[part 6 of 6: packages /DBC_SysDesc_C_CANFD/Pkg_CompuMethod to /DBC_SysDesc_VCU_CAN/Pkg_Units]
AUTOSAR XML (schema 4-2-2)
package /DBC_SysDesc_C_CANFD/Pkg_CompuMethod
  compu method CompuMethod_IBC_CRC_186: raw=phys for phys 0..255
  compu method CompuMethod_IBC_RollingCounter_186: raw=phys for phys 0..15
  compu method CompuMethod_IBC_WheelPressureReliabilityFL: raw=phys for phys 0..1
  compu method CompuMethod_IBC_WheelPressureReliabilityFR: raw=phys for phys 0..1
  compu method CompuMethod_IBC_WheelPressureReliabilityRL: raw=phys for phys 0..1
  compu method CompuMethod_IBC_WheelPressureReliabilityRR: raw=phys for phys 0..1
  compu method CompuMethod_IBC_WheelCylinderPressure_FL: raw=phys*8 for phys 0..255.75
  compu method CompuMethod_IBC_WheelCylinderPressure_FR: raw=phys*8 for phys 0..255.75
  compu method CompuMethod_IBC_WheelCylinderPressure_RL: raw=phys*8 for phys 0..255.75
  compu method CompuMethod_IBC_WheelCylinderPressure_RR: raw=phys*8 for phys 0..255.75
  compu method CompuMethod_IBC_WheelSlipFLVD: raw=phys for phys 0..1
  compu method CompuMethod_IBC_WheelSlipFRVD: raw=phys for phys 0..1
  compu method CompuMethod_IBC_WheelSlipRLVD: raw=phys for phys 0..1
  compu method CompuMethod_IBC_WheelSlipRRVD: raw=phys for phys 0..1
  compu method CompuMethod_IBC_WheelSlipFL: raw=phys+127 for phys -127..127
  compu method CompuMethod_IBC_WheelSlipFR: raw=phys+127 for phys -127..127
  compu method CompuMethod_IBC_WheelSlipRL: raw=phys+127 for phys -127..127
  compu method CompuMethod_IBC_WheelSlipRR: raw=phys+127 for phys -127..127
  compu method CompuMethod_IBC_Slop_Pencent: raw=phys for phys 0..100
  compu method CompuMethod_LMC_CRC_FA: raw=phys for phys 0..255
  compu method CompuMethod_LMC_RollingCounter_FA: raw=phys for phys 0..15
  compu method CompuMethod_LMC_EngTorqDec_Main: raw=phys+400 for phys -400..400
  compu method CompuMethod_LMC_EngTorqDecActive_Main: raw=phys for phys 0..1
  compu method CompuMethod_LMC_AMM_St: raw=phys for phys 0..3
  compu method CompuMethod_LMC_EngTorqInc_Main: raw=phys+400 for phys -400..400
  compu method CompuMethod_LMC_EngTorqIncActive_Main: raw=phys for phys 0..1
  compu method CompuMethod_LMC_EngTorqDec_Sub: raw=phys+400 for phys -400..400
  compu method CompuMethod_LMC_EngTorqDecActive_Sub: raw=phys for phys 0..1
  compu method CompuMethod_LMC_EngTorqInc_Sub: raw=phys+400 for phys -400..400
  compu method CompuMethod_LMC_EngTorqIncActive_Sub: raw=phys for phys 0..1
  compu method CompuMethod_ADDC_CRC_83: raw=phys for phys 0..255
  compu method CompuMethod_ADDC_ACC_AVHReq: raw=phys for phys 0..1
  compu method CompuMethod_ADDC_ACC_HoldSts: raw=phys for phys 0..1
  compu method CompuMethod_ADDC_ACCTargetTrq: raw=phys for phys 0..16383
  compu method CompuMethod_ADDC_ACCTargetTrqVD: raw=phys for phys 0..1
  compu method CompuMethod_ADDC_ACCTargetTrqBrkVD: raw=phys for phys 0..1
  compu method CompuMethod_ADDC_ACCTargetTrqBrk: raw=phys for phys 0..8191
  compu method CompuMethod_ADDC_MAIWarnTrqCtrlFlg: raw=phys for phys 0..7
  compu method CompuMethod_ADDC_RollingCounter_83: raw=phys for phys 0..15
  compu method CompuMethod_ADDC_ACC_FunType: raw=phys for phys 0..3
  compu method CompuMethod_ADDC_ACCMode: raw=phys for phys 0..7
  compu method CompuMethod_ADDC_Driveoff_Request: raw=phys for phys 0..1
  compu method CompuMethod_ADDC_DecToStop: raw=phys for phys 0..1
  compu method CompuMethod_ADDC_ACCAvailable: raw=phys for phys 0..1
  compu method CompuMethod_ADDC_ACCTargetAcc: raw=phys*20+100 for phys -5..7.75
  compu method CompuMethod_ADDC_ACCTargetAccVD: raw=phys for phys 0..1
  compu method CompuMethod_ADDC_ACC_RecordingPulse: raw=phys for phys 0..3
  compu method CompuMethod_ADDC_VehicleSpeedCtlVD: raw=phys for phys 0..1
  compu method CompuMethod_ADDC_VehicleSpeedCtl: raw=phys*10 for phys 0..180
  compu method CompuMethod_ADDC_ACC_EPBReq: raw=phys for phys 0..3
  compu method CompuMethod_ADDC_ACC_VehicleDirectCtl: raw=phys for phys 0..3
  compu method CompuMethod_ADDC_ACC_VehicleDirectCtlVD: raw=phys for phys 0..1
  compu method CompuMethod_ADDC_AEBTargetDec: raw=phys*2000+32000 for phys -16..16
  compu method CompuMethod_ADDC_AEBDecCtrl: raw=phys for phys 0..1
  compu method CompuMethod_ADDC_AEBMode: raw=phys for phys 0..7
  compu method CompuMethod_ADDC_AEBAvailable: raw=phys for phys 0..1
  compu method CompuMethod_ADDC_ACC_VLCCtlReq: raw=phys for phys 0..1
  compu method CompuMethod_ADDC_ACC_OvrdSts: raw=phys for phys 0..1
  compu method CompuMethod_ADDC_RCTB_DecReq: raw=phys for phys 0..1
  compu method CompuMethod_ADDC_RAEB_DecReq: raw=phys for phys 0..1
  compu method CompuMethod_ADDC_MEB_DecReq: raw=phys for phys 0..1
  compu method CompuMethod_LMC_CRC_FD: raw=phys for phys 0..255
  compu method CompuMethod_LMC_RollingCounter_FD: raw=phys for phys 0..15
  compu method CompuMethod_LMC_SysSt: raw=phys for phys 0..3
  compu method CompuMethod_LMC_HSPC_ActiveSt: raw=phys for phys 0..1
  compu method CompuMethod_LMC_FTSC_ActiveSt: raw=phys for phys 0..1
  compu method CompuMethod_LMC_SDRM_ActiveSt: raw=phys for phys 0..1
  compu method CompuMethod_LMC_NSPC_ActiveSt: raw=phys for phys 0..1
  compu method CompuMethod_LMC_EAF_ActiveSt: raw=phys for phys 0..1
  compu method CompuMethod_LMC_SelfCheckSt: raw=phys for phys 0..1
  compu method CompuMethod_LMC_WBDC_ActiveSt: raw=phys for phys 0..3
  compu method CompuMethod_ADDC_CRC_84: raw=phys for phys 0..255
  compu method CompuMethod_ADDC_APS_AVHReq: raw=phys for phys 0..1
  compu method CompuMethod_ADDC_APS_HoldSts: raw=phys for phys 0..1
  compu method CompuMethod_ADDC_APSTargetTrqBrkVD: raw=phys for phys 0..1
  compu method CompuMethod_ADDC_APSTargetTrqBrk: raw=phys for phys 0..8191
  compu method CompuMethod_ADDC_APSTargetTrqVD: raw=phys for phys 0..1
  compu method CompuMethod_ADDC_APSTargetTrq: raw=phys for phys 0..16383
  compu method CompuMethod_ADDC_safety_valid: raw=phys for phys 0..1
  compu method CompuMethod_ADDC_rearsafety_level: raw=phys for phys 0..7
  compu method CompuMethod_ADDC_frontsafety_level: raw=phys for phys 0..7
  compu method CompuMethod_ADDC_rightsafety_level: raw=phys for phys 0..7
  compu method CompuMethod_ADDC_leftsafety_level: raw=phys for phys 0..7
  compu method CompuMethod_ADDC_RollingCounter_84: raw=phys for phys 0..15
  compu method CompuMethod_ADDC_APS_EnableReq: raw=phys for phys 0..1
  compu method CompuMethod_ADDC_APS_WorkSts: raw=phys for phys 0..1
  compu method CompuMethod_ADDC_APS_PDCVehicleDirectCtlVD: raw=phys for phys 0..1
  compu method CompuMethod_ADDC_APS_VehicleSpeedCtlVD: raw=phys for phys 0..1
  compu method CompuMethod_ADDC_APS_PDC_VehicleDirectCtl: raw=phys for phys 0..3
  compu method CompuMethod_ADDC_APS_PDC_SWAngCtl: raw=phys*50+32500 for phys -650..650
  compu method CompuMethod_ADDC_APS_ParkingReq: raw=phys for phys 0..3
  compu method CompuMethod_ADDC_APS_EmergenceBrake: raw=phys for phys 0..1
  compu method CompuMethod_ADDC_APS_TargetAccVD: raw=phys for phys 0..1
  compu method CompuMethod_ADDC_APS_TargetAcc: raw=phys*20+140 for phys -7..5
  compu method CompuMethod_ADDC_APS_VehicleSpeedCtl: raw=phys*8 for phys 0..7.875
  compu method CompuMethod_ADDC_APS_DecToStop: raw=phys for phys 0..1
  compu method CompuMethod_ADDC_APS_Driveoff_Request: raw=phys for phys 0..1
  compu method CompuMethod_ADDC_APS_FuncType: raw=phys for phys 0..7
  compu method CompuMethod_ADDC_APS_Available: raw=phys for phys 0..1
  compu method CompuMethod_IBC_CRC_B1: raw=phys for phys 0..255
  compu method CompuMethod_IBC_RollingCounter_B1: raw=phys for phys 0..15
  compu method CompuMethod_IBC_EngTorqDec_Main: raw=phys+400 for phys -400..400
  compu method CompuMethod_IBC_EngTorqDecActive_Main: raw=phys for phys 0..1
  compu method CompuMethod_IBC_EngTorqInc_Main: raw=phys+400 for phys -400..400
  compu method CompuMethod_IBC_EngTorqIncActive_Main: raw=phys for phys 0..1
  compu method CompuMethod_IBC_EngTorqDec_Sub: raw=phys+400 for phys -400..400
  compu method CompuMethod_IBC_EngTorqDecActive_Sub: raw=phys for phys 0..1
  compu method CompuMethod_IBC_EngTorqInc_Sub: raw=phys+400 for phys -400..400
  compu method CompuMethod_IBC_EngTorqIncActive_Sub: raw=phys for phys 0..1
  compu method CompuMethod_IBC_EngTorqDec_MainR: raw=phys+400 for phys -400..400
  compu method CompuMethod_IBC_EngTorqDecActive_MainR: raw=phys for phys 0..1
  compu method CompuMethod_IBC_EngTorqInc_MainR: raw=phys+400 for phys -400..400
  compu method CompuMethod_IBC_EngTorqIncActive_MainR: raw=phys for phys 0..1
  compu method CompuMethod_IBC_CRC_227: raw=phys for phys 0..255
  compu method CompuMethod_IBC_RollingCounter_227: raw=phys for phys 0..15
  compu method CompuMethod_IBC_EPB_FailStatus: raw=phys for phys 0..3
  compu method CompuMethod_IBC_EPB_Status: raw=phys for phys 0..7
  compu method CompuMethod_IBC_EPB_DrumMode: raw=phys for phys 0..1
  compu method CompuMethod_IBC_EPB_AchievedClampForce: raw=phys for phys 0..255
  compu method CompuMethod_IBC_EPB_FailureLamp: raw=phys for phys 0..3
  compu method CompuMethod_IBC_EPB_ActuatorStateLeft: raw=phys for phys 0..3
  compu method CompuMethod_IBC_EPB_ActuatorStateRight: raw=phys for phys 0..3
  compu method CompuMethod_IBC_EPB_HostAvailabilityLeft: raw=phys for phys 0..3
  compu method CompuMethod_IBC_EPB_HostAvailabilityRight: raw=phys for phys 0..3
  compu method CompuMethod_EPS_CRC_18D: raw=phys for phys 0..255
  compu method CompuMethod_EPS_RollingCounter_18D: raw=phys for phys 0..15
  compu method CompuMethod_EPS_Fault: raw=phys for phys 0..1
  compu method CompuMethod_EPS_CalibrationSts: raw=phys for phys 0..1
  compu method CompuMethod_EPS_FailureSts: raw=phys for phys 0..1
  compu method CompuMethod_EPS_SteeringAngleValidData: raw=phys for phys 0..1
  compu method CompuMethod_EPS_SteeringAngleSpeedValidData: raw=phys for phys 0..1
  compu method CompuMethod_EPS_SteerWheelAngle: raw=phys*50+32500 for phys -650..650
  compu method CompuMethod_EPS_SteerWheelRotSpd: raw=phys*0.25 for phys 0..1016
  compu method CompuMethod_EPS_SelfCheckSt: raw=phys for phys 0..1
  compu method CompuMethod_EPS_AssistanceSts: raw=phys for phys 0..2
  compu method CompuMethod_IBC_CRC_182: raw=phys for phys 0..255
  compu method CompuMethod_IBC_RollingCounter_182: raw=phys for phys 0..15
  compu method CompuMethod_IBC_VehicleSpeed: raw=phys*100 for phys 0..450
  compu method CompuMethod_IBC_VehicleSpeedVD: raw=phys for phys 0..1
  compu method CompuMethod_IBC_ABSActive: raw=phys for phys 0..1
  compu method CompuMethod_IBC_ABSFailed: raw=phys for phys 0..1
  compu method CompuMethod_IBC_TCSActive: raw=phys for phys 0..1
  compu method CompuMethod_IBC_TCSFailed: raw=phys for phys 0..1
  compu method CompuMethod_IBC_ESCFunctionStatus: raw=phys for phys 0..1
  compu method CompuMethod_IBC_BrakeForce: raw=phys for phys 0..1
  compu method CompuMethod_IBC_Vehiclestandstill: raw=phys for phys 0..1
  compu method CompuMethod_IBC_EBDFailed: raw=phys for phys 0..1
  compu method CompuMethod_IBC_EBDActive: raw=phys for phys 0..1
  compu method CompuMethod_IBC_VDCActive: raw=phys for phys 0..1
  compu method CompuMethod_IBC_VDCFailed: raw=phys for phys 0..1
  compu method CompuMethod_IBC_EDCActive: raw=phys for phys 0..1
  compu method CompuMethod_IBC_EDCFailed: raw=phys for phys 0..1
  compu method CompuMethod_IBC_SystemInitializeStatus: raw=phys for phys 0..1
  compu method CompuMethod_IBC_BTCSActive: raw=phys for phys 0..1
  compu method CompuMethod_IBC_ETCSActive: raw=phys for phys 0..1
  compu method CompuMethod_IBC_ARPActive: raw=phys for phys 0..1
  compu method CompuMethod_IBC_VCU_DrumMode: raw=phys for phys 0..1
  compu method CompuMethod_IBC_EscapeModeSts: raw=phys for phys 0..1
  compu method CompuMethod_IBC_CRC_183: raw=phys for phys 0..255
  compu method CompuMethod_IBC_RollingCounter_183: raw=phys for phys 0..15
  compu method CompuMethod_IBC_RecuBrakeTorqueRequest: raw=phys for phys 0..32767
  compu method CompuMethod_IBC_RecuBrakeTorqueRequest_Q: raw=phys for phys 0..3
  compu method CompuMethod_IBC_sOutputRodDriverPer_Q: raw=phys for phys 0..2
  compu method CompuMethod_IBC_BrakePedalApplied_Q: raw=phys for phys 0..3
  compu method CompuMethod_IBC_HydraTorqTgtAct_Q: raw=phys for phys 0..2
  compu method CompuMethod_IBC_HydraTorqTgtAct: raw=phys for phys 0..32767
  compu method CompuMethod_IBC_BrakePedalApplied: raw=phys for phys 0..1
  compu method CompuMethod_IBC_sOutputRodDriverPer: raw=phys for phys 0..100
  compu method CompuMethod_IBC_HydraTorqAvailable: raw=phys for phys 0..1
  compu method CompuMethod_IBC_CtrlMode: raw=phys for phys 0..7
  compu method CompuMethod_IBC_QDC_HydraTorqTgt: raw=phys for phys 0..1
  compu method CompuMethod_IBC_InPutRodDriver: raw=phys*78.125+390.625 for phys -5..47
  compu method CompuMethod_IBC_InPutRodDriver_Q: raw=phys for phys 0..3
  compu method CompuMethod_IBC_SystemAssistedStatus: raw=phys for phys 0..7
  compu method CompuMethod_IBC_EngTorq_VLC_Vaild: raw=phys for phys 0..1
  compu method CompuMethod_IBC_EngTorq_VLC: raw=phys+6000 for phys -6000..10000
  compu method CompuMethod_IBC_BrkTorq_VLC: raw=phys+32767 for phys -32767..0
  compu method CompuMethod_IBC_BrkTorq_VLC_Vaild: raw=phys for phys 0..1
  compu method CompuMethod_ACU_CRC_233: raw=phys for phys 0..255
  compu method CompuMethod_ACU_RollingCounter_233: raw=phys for phys 0..15
  compu method CompuMethod_ACU_LateralAcce: raw=phys*32+512 for phys -16..15.90625
  compu method CompuMethod_ACU_LongitAcce: raw=phys*32+512 for phys -16..15.90625
  compu method CompuMethod_ACU_LateralAcceValid: raw=phys for phys 0..1
  compu method CompuMethod_ACU_LongitAcceValid: raw=phys for phys 0..1
  compu method CompuMethod_ACU_SensorCalSt: raw=phys for phys 0..1
  compu method CompuMethod_ACU_YawRate: raw=phys*100+8191 for phys -81.91..81.91
  compu method CompuMethod_ACU_YawRateValid: raw=phys for phys 0..1
  compu method CompuMethod_IBC_CRC_184: raw=phys for phys 0..255
  compu method CompuMethod_IBC_RollingCounter_184: raw=phys for phys 0..15
  compu method CompuMethod_IBC_FLWheelSpeedKPH: raw=phys*100 for phys 0..450
  compu method CompuMethod_IBC_FRWheelSpeedKPH: raw=phys*100 for phys 0..450
  compu method CompuMethod_IBC_RLWheelSpeedKPH: raw=phys*100 for phys 0..450
  compu method CompuMethod_IBC_RRWheelSpeedKPH: raw=phys*100 for phys 0..450
  compu method CompuMethod_IBC_FLWheelDirection: raw=phys for phys 0..3
  compu method CompuMethod_IBC_FRWheelDirection: raw=phys for phys 0..3
  compu method CompuMethod_IBC_RLWheelDirection: raw=phys for phys 0..3
  compu method CompuMethod_IBC_RRWheelDirection: raw=phys for phys 0..3
  compu method CompuMethod_IBC_FLWheelSpeedVD: raw=phys for phys 0..1
  compu method CompuMethod_IBC_FRWheelSpeedVD: raw=phys for phys 0..1
  compu method CompuMethod_IBC_RLWheelSpeedVD: raw=phys for phys 0..1
  compu method CompuMethod_IBC_RRWheelSpeedVD: raw=phys for phys 0..1
  compu method CompuMethod_IBC_FLWheelSpeedRC: raw=phys for phys 0..4094
  compu method CompuMethod_IBC_FRWheelSpeedRC: raw=phys for phys 0..4094
  compu method CompuMethod_IBC_RLWheelSpeedRC: raw=phys for phys 0..4094
  compu method CompuMethod_IBC_RRWheelSpeedRC: raw=phys for phys 0..4094
  compu method CompuMethod_IBC_DiscTemperatureFL: raw=phys for phys 0..7
  compu method CompuMethod_IBC_DiscTemperatureFLVD: raw=phys for phys 0..1
  compu method CompuMethod_IBC_DiscTemperatureFR: raw=phys for phys 0..7
  compu method CompuMethod_IBC_DiscTemperatureFRVD: raw=phys for phys 0..1
  compu method CompuMethod_IBC_DiscTemperatureRL: raw=phys for phys 0..7
  compu method CompuMethod_IBC_DiscTemperatureRLVD: raw=phys for phys 0..1
  compu method CompuMethod_IBC_DiscTemperatureRR: raw=phys for phys 0..7
  compu method CompuMethod_IBC_DiscTemperatureRRVD: raw=phys for phys 0..1
  compu method CompuMethod_FSC_CRC_142: raw=phys for phys 0..255
  compu method CompuMethod_FSC_RollingCounter_142: raw=phys for phys 0..15
  compu method CompuMethod_FSC_LCC_Mode: raw=phys for phys 0..7
  compu method CompuMethod_IBC_CRC_185: raw=phys for phys 0..255
  compu method CompuMethod_IBC_RollingCounter_185: raw=phys for phys 0..15
  compu method CompuMethod_IBC_PlungerPressure: raw=phys*8 for phys 0..255.75
  compu method CompuMethod_IBC_PlungerPressure_Q: raw=phys for phys 0..1
  compu method CompuMethod_IBC_SimulatorPressure: raw=phys*8 for phys 0..255.75
  compu method CompuMethod_IBC_SimulatorPressure_Q: raw=phys for phys 0..1
  compu method CompuMethod_IBC_HMI_WarningOn: raw=phys for phys 0..3
  compu method CompuMethod_IBC_MIL_WarningOn: raw=phys for phys 0..1
  compu method CompuMethod_IBC_LongitAcceAct: raw=phys*32+512 for phys -16..15.90625
  compu method CompuMethod_IBC_LongitAcceActValid: raw=phys for phys 0..1
  compu method CompuMethod_IBC_brakeFluidWarning: raw=phys for phys 0..3
  compu method CompuMethod_IBC_SCM_Active: raw=phys for phys 0..1
  compu method CompuMethod_IBC_SCM_Failed: raw=phys for phys 0..1
  compu method CompuMethod_IBC_CDPAvailable: raw=phys for phys 0..1
  compu method CompuMethod_IBC_CDPIntervention: raw=phys for phys 0..1
  compu method CompuMethod_IBC_AEB_active: raw=phys for phys 0..1
  compu method CompuMethod_IBC_AEBdecAvailable: raw=phys for phys 0..1
  compu method CompuMethod_IBC_AVHStatus: raw=phys for phys 0..3
  compu method CompuMethod_IBC_AVHAvailable: raw=phys for phys 0..1
  compu method CompuMethod_IBC_HHCActive: raw=phys for phys 0..1
  compu method CompuMethod_IBC_HHCFailed: raw=phys for phys 0..1
  compu method CompuMethod_IBC_CDD_Available_APA: raw=phys for phys 0..1
  compu method CompuMethod_IBC_CDD_Active_APA: raw=phys for phys 0..1
  compu method CompuMethod_IBC_CDD_Available_ACC: raw=phys for phys 0..1
  compu method CompuMethod_IBC_CDD_Active_ACC: raw=phys for phys 0..1
  compu method CompuMethod_IBC_HDCStatus: raw=phys for phys 0..3
  compu method CompuMethod_IBC_HDCAvailable: raw=phys for phys 0..1
  compu method CompuMethod_IBC_CSTStatus: raw=phys for phys 0..3
  compu method CompuMethod_IBC_CSTAvailable: raw=phys for phys 0..1
  compu method CompuMethod_IBC_VLC_Available_ACC: raw=phys for phys 0..1
  compu method CompuMethod_IBC_VLC_Active_ACC: raw=phys for phys 0..1
  compu method CompuMethod_IBC_VLC_Available_APA: raw=phys for phys 0..1
  compu method CompuMethod_IBC_VLC_Active_APA: raw=phys for phys 0..1
  compu method CompuMethod_IBC_VehicleHoldStatus: raw=phys for phys 0..3
  compu method CompuMethod_IBC_DrvrBrkTqAtWhlsReqd: raw=phys for phys 0..32767
  compu method CompuMethod_ACU_CRC_2A3: raw=phys for phys 0..255
  compu method CompuMethod_ACU_Trigger: raw=phys for phys 0..1
  compu method CompuMethod_ACU_RollingCounter_2A3: raw=phys for phys 0..15
  compu method CompuMethod_ACU_TotalCrashOutputSts: raw=phys for phys 0..1
  compu method CompuMethod_ACU_SelfCheckSt: raw=phys for phys 0..1
  compu method CompuMethod_ACU_FLSeatBeltRSt: raw=phys for phys 0..3
  compu method CompuMethod_ACU_FRSeatBeltRSt: raw=phys for phys 0..3
  compu method CompuMethod_ICU_CRC_24D: raw=phys for phys 0..255
  compu method CompuMethod_ICU_SpeedConversionCoefficient: raw=phys for phys 0..3
  compu method CompuMethod_ICU_RollingCounter_24D: raw=phys for phys 0..15
  compu method CompuMethod_ICU_CCSFunctionStatus: raw=phys for phys 0..1
  compu method CompuMethod_ICU_CruiseVehicleSpeedCtl: raw=phys*100 for phys 0..450
  compu method CompuMethod_ICU_VehicleScreenSpeed: raw=phys for phys 0..450
  compu method CompuMethod_ICU_VehicleSpeedUnit: raw=phys for phys 0..1
  compu method CompuMethod_ICU_ACCFunctionStatus: raw=phys for phys 0..1
  compu method CompuMethod_ICU_LCCFunctionStatus: raw=phys for phys 0..1
  compu method CompuMethod_IVI_LPedalMode: raw=phys for phys 0..1
  compu method CompuMethod_BCM_CRC_290: raw=phys for phys 0..255
  compu method CompuMethod_BCM_RRDoorSts_ID290_CCAN: raw=phys for phys 0..1
  compu method CompuMethod_BCM_RLDoorSts_ID290_CCAN: raw=phys for phys 0..1
  compu method CompuMethod_BCM_RollingCounter_290: raw=phys for phys 0..15
  compu method CompuMethod_BCM_HazardSwtSts: raw=phys for phys 0..1
  compu method CompuMethod_BCM_DrOC_PPD_Status: raw=phys for phys 0..3
  compu method CompuMethod_BCM_FLOC_PPD_Status: raw=phys for phys 0..3
  compu method CompuMethod_BCM_FROC_PPD_Status: raw=phys for phys 0..3
  compu method CompuMethod_BCM_DriverDoorSts_ID290_CCAN: raw=phys for phys 0..1
  compu method CompuMethod_BCM_DriverDoorSts_VD: raw=phys for phys 0..1
  compu method CompuMethod_BCM_FLDoorSts_ID290_CCAN: raw=phys for phys 0..1
  compu method CompuMethod_BCM_FRDoorSts_ID290_CCAN: raw=phys for phys 0..1
  compu method CompuMethod_BCM_BackDoorSts_ID290_CCAN: raw=phys for phys 0..1
  compu method CompuMethod_BCM_FrontCoverSts: raw=phys for phys 0..1
  compu method CompuMethod_BCM_HazardSwtOpenSts: raw=phys for phys 0..1
  compu method CompuMethod_BCM_BrakeFluidLevel: raw=phys for phys 0..3
  compu method CompuMethod_BCM_ON2BRelaySts_ID290_CCAN: raw=phys for phys 0..1
  compu method CompuMethod_BCM_ON2CRelaySts_ID290_CCAN: raw=phys for phys 0..1
  compu method CompuMethod_BCM_AlarmMode_C: raw=phys for phys 0..3
  compu method CompuMethod_LMC_LSFCActiveSt: raw=phys for phys 0..3
  compu method CompuMethod_LMC_EngTorqDec_Main_R: raw=phys+400 for phys -400..400
  compu method CompuMethod_LMC_EngTorqDecActive_Main_R: raw=phys for phys 0..1
  compu method CompuMethod_LMC_EngTorqInc_Main_R: raw=phys+400 for phys -400..400
  compu method CompuMethod_LMC_EngTorqIncActive_Main_R: raw=phys for phys 0..1
  compu method CompuMethod_IVI_CRC_331: raw=phys for phys 0..255
  compu method CompuMethod_IVI_RollingCounter_331: raw=phys for phys 0..15
  compu method CompuMethod_IVI_EPBRequst: raw=phys for phys 0..3
  compu method CompuMethod_IVI_TerrainMatchMode: raw=phys for phys 0..7
  compu method CompuMethod_IVI_LPedalModeSW: raw=phys for phys 0..1
  compu method CompuMethod_IVI_AVHSw_X: raw=phys for phys 0..3
  compu method CompuMethod_IVI_ESCSw_X: raw=phys for phys 0..3
  compu method CompuMethod_IVI_HDCSw_X: raw=phys for phys 0..3
  compu method CompuMethod_IVI_CSTSw_X: raw=phys for phys 0..3
  compu method CompuMethod_IVI_AutoAllRoad: raw=phys for phys 0..7
  compu method CompuMethod_IVI_CampingMode_SW: raw=phys for phys 0..1
  compu method CompuMethod_IVI_BraPedMod: raw=phys for phys 0..3
  compu method CompuMethod_IVI_SlowspeedSmartCtrl: raw=phys for phys 0..1
  compu method CompuMethod_IVI_TrailerModeCtrl: raw=phys for phys 0..1
  compu method CompuMethod_IVI_EscapeMode_SW: raw=phys for phys 0..1
  compu method CompuMethod_IVI_PowerSavingModeReq: raw=phys for phys 0..3
  compu method CompuMethod_IVI_SelfAdaptionDriveSW: raw=phys for phys 0..1
  compu method CompuMethod_IVI_CmpUTurnStartUI: raw=phys for phys 0..1
  compu method CompuMethod_IVI_CmpUTurnLockWhlUI: raw=phys for phys 0..7
  compu method CompuMethod_IVI_CmpUTurnTarDirUI: raw=phys for phys 0..3
  compu method CompuMethod_IVI_CmpUTurnTarAngleUI: raw=phys for phys 0..511
  compu method CompuMethod_IVI_CmpUTurnReq: raw=phys for phys 0..3
  compu method CompuMethod_ICU_CRC_332: raw=phys for phys 0..255
  compu method CompuMethod_ICU_RollingCounter_332: raw=phys for phys 0..15
  compu method CompuMethod_ICU_AEB_SW: raw=phys for phys 0..1
  compu method CompuMethod_ICU_ISA_controlSW: raw=phys for phys 0..1
  compu method CompuMethod_ICU_SLIF_SW: raw=phys for phys 0..1
  compu method CompuMethod_ICU_SLWF_SW: raw=phys for phys 0..1
  compu method CompuMethod_VCU_CRC_B6: raw=phys for phys 0..255
  compu method CompuMethod_VCU_TVTest2: raw=phys for phys 0..1048575
  compu method CompuMethod_VCU_VPE_Test1: raw=phys for phys 0..4095
  compu method CompuMethod_VCU_VPE_Test2: raw=phys for phys 0..127
  compu method CompuMethod_VCU_TVTest1: raw=phys for phys 0..32767
  compu method CompuMethod_VCU_RollingCounter_B6: raw=phys for phys 0..15
  compu method CompuMethod_VCU_MDrvRequestTorque_IDB6_CCAN: raw=phys*10+5000 for phys -500..500
  compu method CompuMethod_VCU_MDriverRequireTorque: raw=phys*10+5000 for phys -500..500
  compu method CompuMethod_VCU_SDrvRequestTorque_IDB6_CCAN: raw=phys*10+5000 for phys -500..500
  compu method CompuMethod_VCU_SDriverRequireTorque: raw=phys*10+5000 for phys -500..500
  compu method CompuMethod_VCU_ThrottlePosition_IDB6_CCAN: raw=phys*2.544529262 for phys 0..100
  compu method CompuMethod_VCU_AccPedalValid_IDB6_CCAN: raw=phys for phys 0..1
  compu method CompuMethod_VCU_BrakeSysFault_IDB6_CCAN: raw=phys for phys 0..1
  compu method CompuMethod_VCU_BrakeLightReq: raw=phys for phys 0..1
  compu method CompuMethod_VCU_BrakePedalSts: raw=phys for phys 0..1
  compu method CompuMethod_VCU_BrakePedalStsValid: raw=phys for phys 0..1
  compu method CompuMethod_VCU_GearLevelPosSts_IDB6_CCAN: raw=phys for phys 0..3
  compu method CompuMethod_VCU_GearLeverValid_IDB6_CCAN: raw=phys for phys 0..1
  compu method CompuMethod_VCU_BrakeFirstSts: raw=phys for phys 0..1
  compu method CompuMethod_VCU_DeliveryModeSts_IDB6_CCAN: raw=phys for phys 0..1
  compu method CompuMethod_VCU_MRDrvRequestTorque_IDB6_CCAN: raw=phys*10 for phys -500..500
  compu method CompuMethod_VCU_MRDriverRequireTorque: raw=phys*10 for phys -500..500
  compu method CompuMethod_VCU_CRC_B7: raw=phys for phys 0..255
  compu method CompuMethod_VCU_KeepWorkModeFlag: raw=phys for phys 0..1
  compu method CompuMethod_VCU_MAI_Active: raw=phys for phys 0..1
  compu method CompuMethod_VCU_MAI_Available: raw=phys for phys 0..1
  compu method CompuMethod_VCU_GetCrashStsReq: raw=phys for phys 0..1
  compu method CompuMethod_VCU_ADASPosTorqueCap_VD: raw=phys for phys 0..1
  compu method CompuMethod_VCU_ADASPosTorqueCap: raw=phys for phys 0..16383
  compu method CompuMethod_VCU_RollingCounter_B7: raw=phys for phys 0..15
  compu method CompuMethod_VCU_Vehicle_Warning_IDB7_CCAN: raw=phys for phys 0..3
  compu method CompuMethod_VCU_VehicleSts_IDB7_CCAN: raw=phys for phys 0..1
  compu method CompuMethod_VCU_PowerReduceReq: raw=phys for phys 0..3
  compu method CompuMethod_VCU_ParkingReqToEPB_VD: raw=phys for phys 0..3
  compu method CompuMethod_VCU_ParkingReqToEPB: raw=phys for phys 0..3
  compu method CompuMethod_VCU_ACCAvailable: raw=phys for phys 0..3
  compu method CompuMethod_VCU_ACCActiveSts: raw=phys for phys 0..1
  compu method CompuMethod_VCU_Active_APS: raw=phys for phys 0..1
  compu method CompuMethod_VCU_Available_APS: raw=phys for phys 0..1
  compu method CompuMethod_VCU_ESCActive: raw=phys for phys 0..1
  compu method CompuMethod_VCU_ESCTorqReqAvailability_Rear: raw=phys for phys 0..1
  compu method CompuMethod_VCU_AutoHold_ibit: raw=phys for phys 0..1
  compu method CompuMethod_VCU_VehicleSpeedVD: raw=phys for phys 0..3
  compu method CompuMethod_VCU_CCSStatus: raw=phys for phys 0..3
  compu method CompuMethod_VCU_AutoDriveRequest: raw=phys for phys 0..3
  compu method CompuMethod_VCU_CCSAllow: raw=phys for phys 0..1
  compu method CompuMethod_VCU_VlcHoldSts: raw=phys for phys 0..1
  compu method CompuMethod_VCU_HoldReqSts: raw=phys for phys 0..3
  compu method CompuMethod_VCU_HoldReqStsValid: raw=phys for phys 0..1
  compu method CompuMethod_VCU_DriverAssistProhibitSts_IDB7_CCAN: raw=phys for phys 0..1
  compu method CompuMethod_VCU_SpeedLimitedSts: raw=phys for phys 0..1
  compu method CompuMethod_VCU_SpeedLimitedValue: raw=phys for phys 0..254
  compu method CompuMethod_VCU_TheoAccePedalPercent: raw=phys*2.544529262 for phys 0..100
  compu method CompuMethod_VCU_RecuBrakeTorqueCap: raw=phys for phys 0..32767
  compu method CompuMethod_VCU_RecuBrakeTorqueAct: raw=phys for phys 0..32767
  compu method CompuMethod_VCU_TheoAccePedalValid: raw=phys for phys 0..1
  compu method CompuMethod_VCU_HydraTorqTgt: raw=phys for phys 0..32767
  compu method CompuMethod_VCU_RecuBrakeTorqueActDrag: raw=phys for phys 0..32767
  compu method CompuMethod_VCU_ESCTorqReqAvailability_Frnt: raw=phys for phys 0..1
  compu method CompuMethod_VCU_RecuBrakeTorqueCap_Q: raw=phys for phys 0..3
  compu method CompuMethod_VCU_RecuBrakeTorqueAct_Q: raw=phys for phys 0..3
  compu method CompuMethod_VCU_HydraTorqTgt_Q: raw=phys for phys 0..3
  compu method CompuMethod_VCU_RecuBrakeTorqueActDrag_Q: raw=phys for phys 0..3
  compu method CompuMethod_VCU_RecuBrakeTorqueTarget_Drag: raw=phys for phys 0..32767
  compu method CompuMethod_VCU_PreventVehSlipSts: raw=phys for phys 0..1
  compu method CompuMethod_VCU_RecuBrakeTorqueTarget_Drag_Q: raw=phys for phys 0..3
  compu method CompuMethod_VCU_AllMotWhlTrqFB: raw=phys+6000 for phys -6000..10000
  compu method CompuMethod_VCU_AllMotWhlTrqFB_VD: raw=phys for phys 0..1
  compu method CompuMethod_VCU_TorqueMax_Sub: raw=phys for phys 0..32766
  compu method CompuMethod_VCU_TorqueMax_Sub_VD: raw=phys for phys 0..1
  compu method CompuMethod_VCU_TorqueMax_Main_VD: raw=phys for phys 0..1
  compu method CompuMethod_VCU_LSFC_Allow: raw=phys for phys 0..1
  compu method CompuMethod_VCU_LSFC_Active: raw=phys for phys 0..1
  compu method CompuMethod_VCU_MGCUWorkMode_C: raw=phys for phys 0..3
  compu method CompuMethod_VCU_AllRoadSts: raw=phys for phys 0..7
  compu method CompuMethod_VCU_CmpUTurnAllow: raw=phys for phys 0..1
  compu method CompuMethod_VCU_CmpUTurnSts: raw=phys for phys 0..3
  compu method CompuMethod_VCU_AllowCmpUTurnStartFlag: raw=phys for phys 0..1
  compu method CompuMethod_VCU_CmpUTurnLockWhl: raw=phys for phys 0..7
  compu method CompuMethod_VCU_CmpUTurnActAngle: raw=phys for phys 0..511
  compu method CompuMethod_VCU_CmpUTurnActSpinSpd: raw=phys for phys 0..15
  compu method CompuMethod_VCU_CmpUTurnFltHMI: raw=phys for phys 0..15
  compu method CompuMethod_VCU_TorqueMax_Main: raw=phys for phys 0..32766
  compu method CompuMethod_VCU_EscapeModeSts: raw=phys for phys 0..1
  compu method CompuMethod_VCU_MCUSWorkFailMsg: raw=phys for phys 0..7
  compu method CompuMethod_VCU_EscapeWorkFailMsg: raw=phys for phys 0..7
  compu method CompuMethod_VCU_REClutchFltMsg: raw=phys for phys 0..3
  compu method CompuMethod_IBC_CRC_136: raw=phys for phys 0..255
  compu method CompuMethod_IBC_RollingCounter_136: raw=phys for phys 0..15
  compu method CompuMethod_IBC_ModeMinEDrvTar_FA: raw=phys for phys 0..3
  compu method CompuMethod_IBC_ModeMinEDrvTar_RA: raw=phys for phys 0..3
  compu method CompuMethod_IBC_ModeMaxEDrvTar_FA: raw=phys for phys 0..3
  compu method CompuMethod_IBC_ModeMaxEDrvTar_RA: raw=phys for phys 0..3
  compu method CompuMethod_IBC_torque_distribution_RA_Vaild: raw=phys for phys 0..1
  compu method CompuMethod_IBC_torque_distribution_RA: raw=phys for phys 0..255
  compu method CompuMethod_IBC_mTar_FA: raw=phys for phys 0..65535
  compu method CompuMethod_IBC_mTar_RA: raw=phys for phys 0..65535
  compu method CompuMethod_IBC_iLDC_SWInfo: raw=phys for phys 0..255
  compu method CompuMethod_IBC_Variant_Signal: raw=phys for phys 0..255
  compu method CompuMethod_IBC_nTarMax_FA: raw=phys*64+32768 for phys -512..511
  compu method CompuMethod_IBC_nTarMax_RA: raw=phys*64+32768 for phys -512..511
  compu method CompuMethod_IBC_nTarMin_FA: raw=phys*64+32768 for phys -512..511
  compu method CompuMethod_IBC_nTarMin_RA: raw=phys*64+32768 for phys -512..511
  compu method CompuMethod_MCUM_CRC_135: raw=phys for phys 0..255
  compu method CompuMethod_MCUM_RollingCounter_135: raw=phys for phys 0..15
  compu method CompuMethod_MCUM_LDC_SWInfo: raw=phys for phys 0..65534
  compu method CompuMethod_MCUM_LDC_MTarOut_FA: raw=phys+30000 for phys -30000..30000
  compu method CompuMethod_MCUM_LDC_MTarOut_RA: raw=phys+30000 for phys -30000..30000
  compu method CompuMethod_MCUM_LDC_Available_FA: raw=phys for phys 0..1
  compu method CompuMethod_MCUM_LDC_OperationMode_FA: raw=phys for phys 0..7
  compu method CompuMethod_MCUM_LDC_Available_RA: raw=phys for phys 0..1
  compu method CompuMethod_MCUM_LDC_OperationMode_RA: raw=phys for phys 0..7
  compu method CompuMethod_MCUM_RTE_Exchange_Signal_Status: raw=phys for phys 0..255
  compu method CompuMethod_MCUM_MTarIn_FA: raw=phys for phys 0..65535
  compu method CompuMethod_MCUM_MTarIn_RA: raw=phys for phys 0..65535
  compu method CompuMethod_MCUM_InputQF_FA: raw=phys for phys 0..1
  compu method CompuMethod_MCUM_InputQF_RA: raw=phys for phys 0..1
package /DBC_SysDesc_C_CANFD/Pkg_Units
  unit NOUNIT
package /DBC_SysDesc_VCU_CAN/Pkg_Cluster
  can cluster VCU_CAN: baudrate=500000, protocol-name=CAN
    can physical channel VCU_CAN_Channel: comm-connectors=[Conn_VCU_CAN_MVCU]
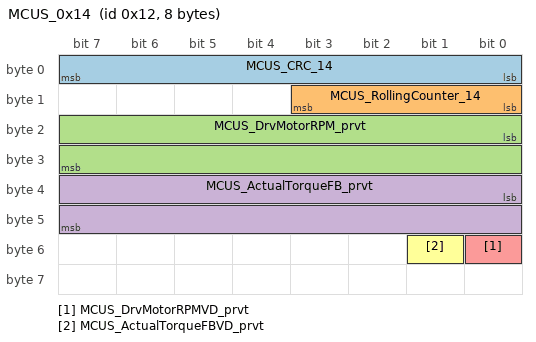
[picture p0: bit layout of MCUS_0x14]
      frame MCUS_0x14: id 0x12, to MVCU, frame-length=8, can-addressing-mode=STANDARD
        carries pdu MCUS_0x14: packing-byte-order=little-endian, start-position=0, update-indication-bit-position=-1
        pdu MCUS_0x14: length=8, transmission-mode-false-timing=cyclic-timing={time-offset=0.0, time-period=0.002}, transmission-mode-true-timing=cyclic-timing={time-offset=0.0, time-period=0.002}
          transmission-mode-conditions:
            {data-filter={data-filter-type=ALWAYS, max=255, min=0, offset=0}, i-signal-in-i-pdu=MCUS_CRC_14}
            {data-filter={data-filter-type=ALWAYS, max=15, min=0, offset=0}, i-signal-in-i-pdu=MCUS_RollingCounter_14}
            {data-filter={data-filter-type=NEW-IS-WITHIN, max=47000, min=0}, i-signal-in-i-pdu=MCUS_DrvMotorRPM_prvt}
            {data-filter={data-filter-type=NEW-IS-WITHIN, max=10000, min=0}, i-signal-in-i-pdu=MCUS_ActualTorqueFB_prvt}
            {data-filter={data-filter-type=ALWAYS, max=1, min=0, offset=0}, i-signal-in-i-pdu=MCUS_DrvMotorRPMVD_prvt}
            {data-filter={data-filter-type=ALWAYS, max=1, min=0, offset=0}, i-signal-in-i-pdu=MCUS_ActualTorqueFBVD_prvt}
          signal MCUS_CRC_14: start 0, 8 bit, little-endian, init-value=0, base-type=uint8, implementation-data-type=DT_MCUS_CRC_14, update-indication-bit-position=-1, to MVCU
          signal MCUS_RollingCounter_14: start 8, 4 bit, little-endian, init-value=0, base-type=uint8, implementation-data-type=DT_MCUS_RollingCounter_14, update-indication-bit-position=-1, to MVCU
          signal MCUS_DrvMotorRPM_prvt: start 16, 16 bit, little-endian, init-value=0, base-type=uint16, implementation-data-type=DT_MCUS_DrvMotorRPM_prvt, update-indication-bit-position=-1, to MVCU
          signal MCUS_ActualTorqueFB_prvt: start 32, 16 bit, little-endian, init-value=0, base-type=uint16, implementation-data-type=DT_MCUS_ActualTorqueFB_prvt, update-indication-bit-position=-1, to MVCU
          signal MCUS_DrvMotorRPMVD_prvt: start 48, 1 bit, little-endian, init-value=0, base-type=uint8, implementation-data-type=DT_MCUS_DrvMotorRPMVD_prvt, update-indication-bit-position=-1, to MVCU
          signal MCUS_ActualTorqueFBVD_prvt: start 49, 1 bit, little-endian, init-value=0, base-type=uint8, implementation-data-type=DT_MCUS_ActualTorqueFBVD_prvt, update-indication-bit-position=-1, to MVCU
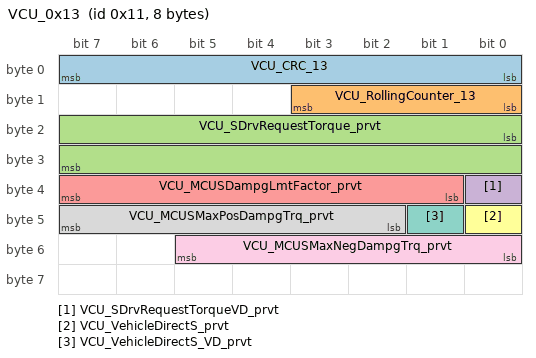
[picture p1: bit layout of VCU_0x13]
      frame VCU_0x13: id 0x11, from MVCU, frame-length=8, can-addressing-mode=STANDARD, can-frame-tx-behavior=CAN-20
        carries pdu VCU_0x13: packing-byte-order=little-endian, start-position=0, update-indication-bit-position=-1
        pdu VCU_0x13: length=8, transmission-mode-false-timing=cyclic-timing={time-offset=0.0, time-period=0.002}, transmission-mode-true-timing=cyclic-timing={time-offset=0.0, time-period=0.002}
          transmission-mode-conditions:
            {data-filter={data-filter-type=ALWAYS, max=255, min=0, offset=0}, i-signal-in-i-pdu=VCU_CRC_13}
            {data-filter={data-filter-type=ALWAYS, max=15, min=0, offset=0}, i-signal-in-i-pdu=VCU_RollingCounter_13}
            {data-filter={data-filter-type=NEW-IS-WITHIN, max=10000, min=0}, i-signal-in-i-pdu=VCU_SDrvRequestTorque_prvt}
            {data-filter={data-filter-type=ALWAYS, max=1, min=0, offset=0}, i-signal-in-i-pdu=VCU_SDrvRequestTorqueVD_prvt}
            {data-filter={data-filter-type=ALWAYS, max=100, min=0, offset=0}, i-signal-in-i-pdu=VCU_MCUSDampgLmtFactor_prvt}
            {data-filter={data-filter-type=ALWAYS, max=1, min=0, offset=0}, i-signal-in-i-pdu=VCU_VehicleDirectS_prvt}
            {data-filter={data-filter-type=ALWAYS, max=1, min=0, offset=0}, i-signal-in-i-pdu=VCU_VehicleDirectS_VD_prvt}
            {data-filter={data-filter-type=ALWAYS, max=50, min=0, offset=0}, i-signal-in-i-pdu=VCU_MCUSMaxPosDampgTrq_prvt}
            {data-filter={data-filter-type=ALWAYS, max=50, min=0}, i-signal-in-i-pdu=VCU_MCUSMaxNegDampgTrq_prvt}
          signal VCU_CRC_13: start 0, 8 bit, little-endian, init-value=0, base-type=uint8, implementation-data-type=DT_VCU_CRC_13, update-indication-bit-position=-1
          signal VCU_RollingCounter_13: start 8, 4 bit, little-endian, init-value=0, base-type=uint8, implementation-data-type=DT_VCU_RollingCounter_13, update-indication-bit-position=-1
          signal VCU_SDrvRequestTorque_prvt: start 16, 16 bit, little-endian, init-value=0, base-type=uint16, implementation-data-type=DT_VCU_SDrvRequestTorque_prvt, update-indication-bit-position=-1
          signal VCU_SDrvRequestTorqueVD_prvt: start 32, 1 bit, little-endian, init-value=0, base-type=uint8, implementation-data-type=DT_VCU_SDrvRequestTorqueVD_prvt, update-indication-bit-position=-1
          signal VCU_MCUSDampgLmtFactor_prvt: start 33, 7 bit, little-endian, init-value=0, base-type=uint8, implementation-data-type=DT_VCU_MCUSDampgLmtFactor_prvt, update-indication-bit-position=-1
          signal VCU_VehicleDirectS_prvt: start 40, 1 bit, little-endian, init-value=0, base-type=uint8, implementation-data-type=DT_VCU_VehicleDirectS_prvt, update-indication-bit-position=-1
          signal VCU_VehicleDirectS_VD_prvt: start 41, 1 bit, little-endian, init-value=0, base-type=uint8, implementation-data-type=DT_VCU_VehicleDirectS_VD_prvt, update-indication-bit-position=-1
          signal VCU_MCUSMaxPosDampgTrq_prvt: start 42, 6 bit, little-endian, init-value=0, base-type=uint8, implementation-data-type=DT_VCU_MCUSMaxPosDampgTrq_prvt, update-indication-bit-position=-1
          signal VCU_MCUSMaxNegDampgTrq_prvt: start 48, 6 bit, little-endian, init-value=0, base-type=uint8, implementation-data-type=DT_VCU_MCUSMaxNegDampgTrq_prvt, update-indication-bit-position=-1
      frame HPCBCM_0xDA: id 0xDA, to MVCU, frame-length=1, can-addressing-mode=STANDARD, can-fd-frame-support=true, can-frame-rx-behavior=CAN-FD
        carries pdu HPCBCM_0xDA: packing-byte-order=little-endian, start-position=0, update-indication-bit-position=-1
        pdu HPCBCM_0xDA: length=16, transmission-mode-false-timing=cyclic-timing={time-offset=0.0, time-period=0.01}, transmission-mode-true-timing=cyclic-timing={time-offset=0.0, time-period=0.01}
          transmission-mode-conditions:
            {data-filter={data-filter-type=ALWAYS, max=255, min=0, offset=0}, i-signal-in-i-pdu=BCM_CRC_DA}
            {data-filter={data-filter-type=ALWAYS, max=15, min=0, offset=0}, i-signal-in-i-pdu=BCM_RollingCounter_DA}
            {data-filter={data-filter-type=ALWAYS, max=65535, min=0, offset=0}, i-signal-in-i-pdu=BCM_IMU_ACC_x}
            {data-filter={data-filter-type=ALWAYS, max=65535, min=0, offset=0}, i-signal-in-i-pdu=BCM_IMU_ACC_y}
            {data-filter={data-filter-type=ALWAYS, max=65535, min=0, offset=0}, i-signal-in-i-pdu=BCM_IMU_ACC_z}
            {data-filter={data-filter-type=ALWAYS, max=65535, min=0, offset=0}, i-signal-in-i-pdu=BCM_IMU_ACC_Roll_Rate}
            {data-filter={data-filter-type=ALWAYS, max=65535, min=0, offset=0}, i-signal-in-i-pdu=BCM_IMU_ACC_Pitch_Rate}
            {data-filter={data-filter-type=ALWAYS, max=65535, min=0, offset=0}, i-signal-in-i-pdu=BCM_IMU_ACC_Yaw_Rate}
            {data-filter={data-filter-type=ALWAYS, max=1, min=0, offset=0}, i-signal-in-i-pdu=BCM_IMU_Valid}
          signal BCM_CRC_DA: start 0, 8 bit, little-endian, init-value=0, base-type=uint8, compu {raw=phys for phys 0..255; unit Pkg_Units/NOUNIT}, update-indication-bit-position=-1, to MVCU  # Ð£ÑéÎ»"
          signal BCM_RollingCounter_DA: start 8, 4 bit, little-endian, init-value=0, base-type=uint8, compu {raw=phys for phys 0..15; unit Pkg_Units/NOUNIT}, update-indication-bit-position=-1, to MVCU  # Ð£ÑéÎ»"
          signal BCM_IMU_ACC_x: start 16, 16 bit, little-endian, init-value=0, base-type=uint16, compu {raw=phys for phys 0..65535; unit Pkg_Units/NOUNIT}, update-indication-bit-position=-1, to MVCU  # Ð£ÑéÎ»"
          signal BCM_IMU_ACC_y: start 32, 16 bit, little-endian, init-value=0, base-type=uint16, compu {raw=phys for phys 0..65535; unit Pkg_Units/NOUNIT}, update-indication-bit-position=-1, to MVCU  # Ð£ÑéÎ»"
          signal BCM_IMU_ACC_z: start 48, 16 bit, little-endian, init-value=0, base-type=uint16, compu {raw=phys for phys 0..65535; unit Pkg_Units/NOUNIT}, update-indication-bit-position=-1, to MVCU  # Ð£ÑéÎ»"
          signal BCM_IMU_ACC_Roll_Rate: start 64, 16 bit, little-endian, init-value=0, base-type=uint16, compu {raw=phys for phys 0..65535; unit Pkg_Units/NOUNIT}, update-indication-bit-position=-1, to MVCU  # Ð£ÑéÎ»"
          signal BCM_IMU_ACC_Pitch_Rate: start 80, 16 bit, little-endian, init-value=0, base-type=uint16, compu {raw=phys for phys 0..65535; unit Pkg_Units/NOUNIT}, update-indication-bit-position=-1, to MVCU  # Ð£ÑéÎ»"
          signal BCM_IMU_ACC_Yaw_Rate: start 96, 16 bit, little-endian, init-value=0, base-type=uint16, compu {raw=phys for phys 0..65535; unit Pkg_Units/NOUNIT}, update-indication-bit-position=-1, to MVCU  # Ð£ÑéÎ»"
          signal BCM_IMU_Valid: start 114, 1 bit, little-endian, init-value=0, base-type=uint8, compu {raw=phys for phys 0..1; unit Pkg_Units/NOUNIT}, update-indication-bit-position=-1, to MVCU  # Ð£ÑéÎ»"
      frame ACU_0x15: id 0x15, to MVCU, frame-length=1, can-addressing-mode=STANDARD, can-fd-frame-support=true, can-frame-rx-behavior=CAN-FD
        carries pdu ACU_0x15: packing-byte-order=little-endian, start-position=0, update-indication-bit-position=-1
        pdu ACU_0x15: length=32, transmission-mode-false-timing=cyclic-timing={time-offset=0.0, time-period=0.002}, transmission-mode-true-timing=cyclic-timing={time-offset=0.0, time-period=0.002}
          transmission-mode-conditions:
            {data-filter={data-filter-type=ALWAYS, max=255, min=0, offset=0}, i-signal-in-i-pdu=ACU_IMU_CRC_15}
            {data-filter={data-filter-type=ALWAYS, max=255, min=0, offset=0}, i-signal-in-i-pdu=ACU_IMU_RollingCounter_15}
            {data-filter={data-filter-type=ALWAYS, max=65535, min=0, offset=0}, i-signal-in-i-pdu=ACU_IMU_ACC_x}
            {data-filter={data-filter-type=ALWAYS, max=65535, min=0, offset=0}, i-signal-in-i-pdu=ACU_IMU_ACC_y}
            {data-filter={data-filter-type=ALWAYS, max=65535, min=0, offset=0}, i-signal-in-i-pdu=ACU_IMU_ACC_z}
            {data-filter={data-filter-type=ALWAYS, max=65535, min=0, offset=0}, i-signal-in-i-pdu=ACU_IMU_Roll_Rate}
            {data-filter={data-filter-type=ALWAYS, max=65535, min=0, offset=0}, i-signal-in-i-pdu=ACU_IMU_Pitch_Rate}
            {data-filter={data-filter-type=ALWAYS, max=65535, min=0, offset=0}, i-signal-in-i-pdu=ACU_IMU_Yaw_Rate}
            {data-filter={data-filter-type=ALWAYS, max=3, min=0, offset=0}, i-signal-in-i-pdu=ACU_IMU_Calibrated}
            {data-filter={data-filter-type=ALWAYS, max=1, min=0, offset=0}, i-signal-in-i-pdu=ACU_IMU_Valid}
            {data-filter={data-filter-type=ALWAYS, max=1, min=0, offset=0}, i-signal-in-i-pdu=ACU_IMU_Fault_Status}
            {data-filter={data-filter-type=ALWAYS, max=7, min=0, offset=0}, i-signal-in-i-pdu=ACU_IMU_MessageStatus}
            {data-filter={data-filter-type=ALWAYS, max=15, min=0, offset=0}, i-signal-in-i-pdu=ACU_IMU_FunctionSafetyStatus}
            {data-filter={data-filter-type=ALWAYS, max=65535, min=0, offset=0}, i-signal-in-i-pdu=ACU_IMU_Temperature}
          signal ACU_IMU_CRC_15: start 0, 8 bit, little-endian, init-value=0, base-type=uint8, compu {raw=phys for phys 0..255; unit Pkg_Units/NOUNIT}, update-indication-bit-position=-1, to MVCU  # Ð£ÑéÎ»"
          signal ACU_IMU_RollingCounter_15: start 8, 8 bit, little-endian, init-value=0, base-type=uint8, compu {raw=phys for phys 0..255; unit Pkg_Units/NOUNIT}, update-indication-bit-position=-1, to MVCU  # Ð£ÑéÎ»"
          signal ACU_IMU_ACC_x: start 16, 16 bit, little-endian, init-value=0, base-type=uint16, compu {raw=phys for phys 0..65535; unit Pkg_Units/NOUNIT}, update-indication-bit-position=-1, to MVCU  # Ð£ÑéÎ»"
          signal ACU_IMU_ACC_y: start 32, 16 bit, little-endian, init-value=0, base-type=uint16, compu {raw=phys for phys 0..65535; unit Pkg_Units/NOUNIT}, update-indication-bit-position=-1, to MVCU  # Ð£ÑéÎ»"
          signal ACU_IMU_ACC_z: start 48, 16 bit, little-endian, init-value=0, base-type=uint16, compu {raw=phys for phys 0..65535; unit Pkg_Units/NOUNIT}, update-indication-bit-position=-1, to MVCU  # Ð£ÑéÎ»"
          signal ACU_IMU_Roll_Rate: start 64, 16 bit, little-endian, init-value=0, base-type=uint16, compu {raw=phys for phys 0..65535; unit Pkg_Units/NOUNIT}, update-indication-bit-position=-1, to MVCU  # Ð£ÑéÎ»"
          signal ACU_IMU_Pitch_Rate: start 80, 16 bit, little-endian, init-value=0, base-type=uint16, compu {raw=phys for phys 0..65535; unit Pkg_Units/NOUNIT}, update-indication-bit-position=-1, to MVCU  # Ð£ÑéÎ»"
          signal ACU_IMU_Yaw_Rate: start 96, 16 bit, little-endian, init-value=0, base-type=uint16, compu {raw=phys for phys 0..65535; unit Pkg_Units/NOUNIT}, update-indication-bit-position=-1, to MVCU  # Ð£ÑéÎ»"
          signal ACU_IMU_Calibrated: start 112, 2 bit, little-endian, init-value=0, base-type=uint8, compu {raw=phys for phys 0..3; unit Pkg_Units/NOUNIT}, update-indication-bit-position=-1, to MVCU  # Ð£ÑéÎ»"
          signal ACU_IMU_Valid: start 114, 1 bit, little-endian, init-value=0, base-type=uint8, compu {raw=phys for phys 0..1; unit Pkg_Units/NOUNIT}, update-indication-bit-position=-1, to MVCU  # Ð£ÑéÎ»"
          signal ACU_IMU_Fault_Status: start 216, 1 bit, little-endian, init-value=0, base-type=uint8, compu {raw=phys for phys 0..1; unit Pkg_Units/NOUNIT}, update-indication-bit-position=-1, to MVCU  # Ð£ÑéÎ»"
          signal ACU_IMU_MessageStatus: start 217, 3 bit, little-endian, init-value=0, base-type=uint8, compu {raw=phys for phys 0..7; unit Pkg_Units/NOUNIT}, update-indication-bit-position=-1, to MVCU  # Ð£ÑéÎ»"
          signal ACU_IMU_FunctionSafetyStatus: start 220, 4 bit, little-endian, init-value=0, base-type=uint8, compu {raw=phys for phys 0..15; unit Pkg_Units/NOUNIT}, update-indication-bit-position=-1, to MVCU  # Ð£ÑéÎ»"
          signal ACU_IMU_Temperature: start 224, 16 bit, little-endian, init-value=0, base-type=uint16, compu {raw=phys for phys 0..65535; unit Pkg_Units/NOUNIT}, update-indication-bit-position=-1, to MVCU  # Ð£ÑéÎ»"
      frame ICU_0x5BE: id 0x5BE, to MVCU, frame-length=2, can-addressing-mode=STANDARD, can-fd-frame-support=true, can-frame-rx-behavior=CAN-FD
        carries pdu ICU_0x5BE: packing-byte-order=little-endian, start-position=0, update-indication-bit-position=-1
        pdu ICU_0x5BE: length=2, transmission-mode-false-timing=cyclic-timing={time-offset=0.0, time-period=0.5}, transmission-mode-true-timing=cyclic-timing={time-offset=0.0, time-period=0.5}
          transmission-mode-conditions:
            {data-filter={data-filter-type=ALWAYS, max=15, min=0, offset=0}, i-signal-in-i-pdu=ICU_RollingCounter_5BE}
            {data-filter={data-filter-type=ALWAYS, max=3, min=0, offset=0}, i-signal-in-i-pdu=ICU_Imu_Cal_Staus}
            {data-filter={data-filter-type=ALWAYS, max=255, min=0, offset=0}, i-signal-in-i-pdu=ICU_Imu_Cal_Gyro}
            {data-filter={data-filter-type=ALWAYS, max=255, min=0, offset=0}, i-signal-in-i-pdu=ICU_Imu_Cal_Pitch}
            {data-filter={data-filter-type=ALWAYS, max=255, min=0, offset=0}, i-signal-in-i-pdu=ICU_Imu_Cal_Roll}
          signal ICU_RollingCounter_5BE: start 8, 4 bit, little-endian, init-value=0, compu {raw=phys for phys 0..15; unit Pkg_Units/NOUNIT}, update-indication-bit-position=-1, to MVCU  # ÉúÃüÐÅºÅ"  # Ð£ÑéÎ»"
          signal ICU_Imu_Cal_Staus: start 40, 2 bit, little-endian, init-value=0, compu {raw=phys for phys 0..3; unit Pkg_Units/NOUNIT}, update-indication-bit-position=-1, to MVCU  # ÉúÃüÐÅºÅ"  # Ð£ÑéÎ»"
          signal ICU_Imu_Cal_Gyro: start 32, 8 bit, little-endian, init-value=0, compu {raw=phys for phys 0..255; unit Pkg_Units/NOUNIT}, update-indication-bit-position=-1, to MVCU  # ÉúÃüÐÅºÅ"  # Ð£ÑéÎ»"
          signal ICU_Imu_Cal_Pitch: start 24, 8 bit, little-endian, init-value=0, compu {raw=phys for phys 0..255; unit Pkg_Units/NOUNIT}, update-indication-bit-position=-1, to MVCU  # ÉúÃüÐÅºÅ"  # Ð£ÑéÎ»"
          signal ICU_Imu_Cal_Roll: start 16, 8 bit, little-endian, init-value=0, compu {raw=phys for phys 0..255; unit Pkg_Units/NOUNIT}, update-indication-bit-position=-1, to MVCU  # ÉúÃüÐÅºÅ"  # Ð£ÑéÎ»"
package /DBC_SysDesc_VCU_CAN/Pkg_CompuMethod
  compu method CompuMethod_MCUS_CRC_14: raw=phys for phys 0..255
  compu method CompuMethod_MCUS_RollingCounter_14: raw=phys for phys 0..15
  compu method CompuMethod_MCUS_DrvMotorRPM_prvt: raw=phys+17000 for phys -17000..30000
  compu method CompuMethod_MCUS_ActualTorqueFB_prvt: raw=phys*10+5000 for phys -500..500
  compu method CompuMethod_MCUS_DrvMotorRPMVD_prvt: raw=phys for phys 0..1
  compu method CompuMethod_MCUS_ActualTorqueFBVD_prvt: raw=phys for phys 0..1
  compu method CompuMethod_VCU_CRC_13: raw=phys for phys 0..255
  compu method CompuMethod_VCU_RollingCounter_13: raw=phys for phys 0..15
  compu method CompuMethod_VCU_SDrvRequestTorque_prvt: raw=phys*10+5000 for phys -500..500
  compu method CompuMethod_VCU_SDrvRequestTorqueVD_prvt: raw=phys for phys 0..1
  compu method CompuMethod_VCU_MCUSDampgLmtFactor_prvt: raw=phys for phys 0..100
  compu method CompuMethod_VCU_VehicleDirectS_prvt: raw=phys for phys 0..1
  compu method CompuMethod_VCU_VehicleDirectS_VD_prvt: raw=phys for phys 0..1
  compu method CompuMethod_VCU_MCUSMaxPosDampgTrq_prvt: raw=phys for phys 0..50
  compu method CompuMethod_VCU_MCUSMaxNegDampgTrq_prvt: raw=phys+50 for phys -50..0
package /DBC_SysDesc_VCU_CAN/Pkg_Units
  unit NOUNIT
